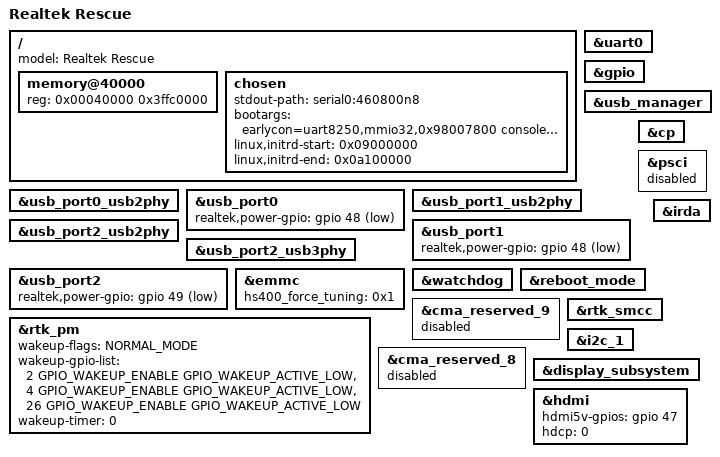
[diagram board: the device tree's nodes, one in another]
// SPDX-License-Identifier: (GPL-2.0-or-later OR BSD-2-Clause)
/*
 * Copyright (c) 2019-2022 Realtek Semiconductor Corp.
 */

/dts-v1/;

#include "rtd13xxd.dtsi"
#include <dt-bindings/soc/realtek,pm.h>

/ {
	model = "Realtek Rescue";

	memory@40000 {
		device_type = "memory";
		reg = <0x00040000 0x3ffc0000>; /* boot ROM to 1 GiB or 2 GiB */
	};

	chosen {
		stdout-path = "serial0:460800n8";
		bootargs = "earlycon=uart8250,mmio32,0x98007800 console=ttyS0,460800 8250.nr_uarts=3 init=/init";
		linux,initrd-start = <0x09000000>;
		linux,initrd-end = <0x0a100000>;
	};
};

/* debug console (J1) */
&uart0 {
	status = "okay";
};

&gpio {
	status = "okay";
};

&usb_manager {
	status = "okay";
};

&usb_port0_usb2phy {
	status = "okay";
};

&usb_port0 {
	realtek,power-gpio = <&gpio 48 GPIO_ACTIVE_LOW>;
	status = "okay";
};

&usb_port1_usb2phy {
	status = "okay";
};

&usb_port1 {
	realtek,power-gpio = <&gpio 48 GPIO_ACTIVE_LOW>;
	status = "okay";
};

&usb_port2_usb2phy {
	status = "okay";
};

&usb_port2_usb3phy {
	status = "okay";
};

&usb_port2 {
	realtek,power-gpio = <&gpio 49 GPIO_ACTIVE_LOW>;
	status = "okay";
};

/delete-node/ &type_c;

&emmc {
	hs400_force_tuning = <0x1>;
	status = "okay";
};

&cp {
	status = "okay";
};

&psci {
	status = "disabled";
};

&watchdog {
	status = "okay";
};

&reboot_mode {
	status = "okay";
};

&irda {
	status = "okay";
};

&cma_reserved_9 {
	status = "disabled";
};

&rtk_pm {
	wakeup-flags = <NORMAL_MODE>;
	wakeup-gpio-list = <2 GPIO_WAKEUP_ENABLE GPIO_WAKEUP_ACTIVE_LOW>,
			   <4 GPIO_WAKEUP_ENABLE GPIO_WAKEUP_ACTIVE_LOW>,
			   <26 GPIO_WAKEUP_ENABLE GPIO_WAKEUP_ACTIVE_LOW>;
	wakeup-timer = <0>;
	status = "okay";
};

&rtk_smcc {
	status = "okay";
};

&cma_reserved_8 {
	status = "disabled";
};

&i2c_1 {
	status = "okay";
};

&display_subsystem {
	status = "okay";
};

&hdmi {
	hdmi5v-gpios = <&gpio 47 GPIO_ACTIVE_HIGH>;
	hdcp = <0>;
};
